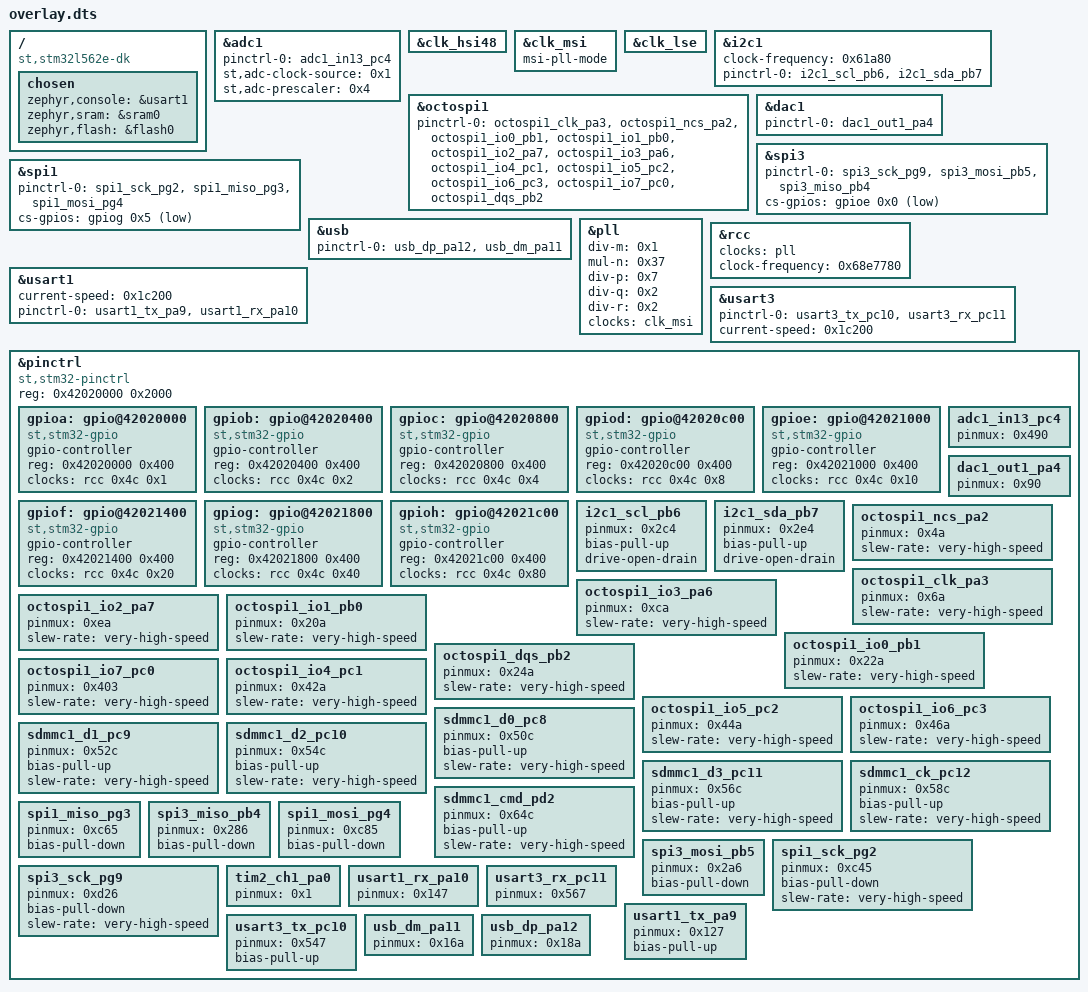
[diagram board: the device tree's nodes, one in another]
/ {
	compatible = "st,stm32l562e-dk";
	chosen {
		zephyr,console = &usart1;
		zephyr,sram = &sram0;
		zephyr,flash = &flash0;
	};
};
&adc1{
	status = "okay";
	pinctrl-0 = < &adc1_in13_pc4 >;
	pinctrl-names = "default";
	st,adc-clock-source = < 0x1 >;
	st,adc-prescaler = < 0x4 >;
};
&clk_hsi48{
	status = "okay";
};
&clk_msi{
	status = "okay";
	msi-pll-mode;
};
&clk_lse{
	status = "okay";
};
&i2c1{
	clock-frequency = < 0x61a80 >;
	status = "okay";
	pinctrl-0 = < &i2c1_scl_pb6 &i2c1_sda_pb7 >;
	pinctrl-names = "default";
};
&octospi1{
	status = "okay";
	pinctrl-0 = < &octospi1_clk_pa3 &octospi1_ncs_pa2 &octospi1_io0_pb1 &octospi1_io1_pb0 &octospi1_io2_pa7 &octospi1_io3_pa6 &octospi1_io4_pc1 &octospi1_io5_pc2 &octospi1_io6_pc3 &octospi1_io7_pc0 &octospi1_dqs_pb2 >;
	pinctrl-names = "default";
};
&dac1{
	status = "okay";
	pinctrl-0 = < &dac1_out1_pa4 >;
	pinctrl-names = "default";
};
&spi3{
	status = "okay";
	pinctrl-0 = < &spi3_sck_pg9 &spi3_mosi_pb5 &spi3_miso_pb4 >;
	pinctrl-names = "default";
	cs-gpios = < &gpioe 0x0 0x11 >;
};
&spi1{
	status = "okay";
	pinctrl-0 = < &spi1_sck_pg2 &spi1_miso_pg3 &spi1_mosi_pg4 >;
	pinctrl-names = "default";
	cs-gpios = < &gpiog 0x5 0x11 >;
};
&usb{
	status = "okay";
	pinctrl-0 = < &usb_dp_pa12 &usb_dm_pa11 >;
	pinctrl-names = "default";
};
&pll{
	status = "okay";
	div-m = < 0x1 >;
	mul-n = < 0x37 >;
	div-p = < 0x7 >;
	div-q = < 0x2 >;
	div-r = < 0x2 >;
	clocks = < &clk_msi >;
};
&rcc{
	clocks = < &pll >;
	clock-frequency = < 0x68e7780 >;
};
&usart1{
	status = "okay";
	current-speed = < 0x1c200 >;
	pinctrl-0 = < &usart1_tx_pa9 &usart1_rx_pa10 >;
	pinctrl-names = "default";
};
&usart3{
	status = "okay";
	pinctrl-0 = < &usart3_tx_pc10 &usart3_rx_pc11 >;
	pinctrl-names = "default";
	current-speed = < 0x1c200 >;
};
&pinctrl{
	compatible = "st,stm32-pinctrl";
	#address-cells = < 0x1 >;
	#size-cells = < 0x1 >;
	reg = < 0x42020000 0x2000 >;
	gpioa: gpio@42020000 {
		compatible = "st,stm32-gpio";
		gpio-controller;
		#gpio-cells = < 0x2 >;
		reg = < 0x42020000 0x400 >;
		clocks = < &rcc 0x4c 0x1 >;
	};
	gpiob: gpio@42020400 {
		compatible = "st,stm32-gpio";
		gpio-controller;
		#gpio-cells = < 0x2 >;
		reg = < 0x42020400 0x400 >;
		clocks = < &rcc 0x4c 0x2 >;
	};
	gpioc: gpio@42020800 {
		compatible = "st,stm32-gpio";
		gpio-controller;
		#gpio-cells = < 0x2 >;
		reg = < 0x42020800 0x400 >;
		clocks = < &rcc 0x4c 0x4 >;
	};
	gpiod: gpio@42020c00 {
		compatible = "st,stm32-gpio";
		gpio-controller;
		#gpio-cells = < 0x2 >;
		reg = < 0x42020c00 0x400 >;
		clocks = < &rcc 0x4c 0x8 >;
	};
	gpioe: gpio@42021000 {
		compatible = "st,stm32-gpio";
		gpio-controller;
		#gpio-cells = < 0x2 >;
		reg = < 0x42021000 0x400 >;
		clocks = < &rcc 0x4c 0x10 >;
	};
	gpiof: gpio@42021400 {
		compatible = "st,stm32-gpio";
		gpio-controller;
		#gpio-cells = < 0x2 >;
		reg = < 0x42021400 0x400 >;
		clocks = < &rcc 0x4c 0x20 >;
	};
	gpiog: gpio@42021800 {
		compatible = "st,stm32-gpio";
		gpio-controller;
		#gpio-cells = < 0x2 >;
		reg = < 0x42021800 0x400 >;
		clocks = < &rcc 0x4c 0x40 >;
	};
	gpioh: gpio@42021c00 {
		compatible = "st,stm32-gpio";
		gpio-controller;
		#gpio-cells = < 0x2 >;
		reg = < 0x42021c00 0x400 >;
		clocks = < &rcc 0x4c 0x80 >;
	};
	adc1_in13_pc4: adc1_in13_pc4 {
		pinmux = < 0x490 >;
	};
	dac1_out1_pa4: dac1_out1_pa4 {
		pinmux = < 0x90 >;
	};
	i2c1_scl_pb6: i2c1_scl_pb6 {
		pinmux = < 0x2c4 >;
		bias-pull-up;
		drive-open-drain;
	};
	i2c1_sda_pb7: i2c1_sda_pb7 {
		pinmux = < 0x2e4 >;
		bias-pull-up;
		drive-open-drain;
	};
	octospi1_ncs_pa2: octospi1_ncs_pa2 {
		pinmux = < 0x4a >;
		slew-rate = "very-high-speed";
	};
	octospi1_clk_pa3: octospi1_clk_pa3 {
		pinmux = < 0x6a >;
		slew-rate = "very-high-speed";
	};
	octospi1_io3_pa6: octospi1_io3_pa6 {
		pinmux = < 0xca >;
		slew-rate = "very-high-speed";
	};
	octospi1_io2_pa7: octospi1_io2_pa7 {
		pinmux = < 0xea >;
		slew-rate = "very-high-speed";
	};
	octospi1_io1_pb0: octospi1_io1_pb0 {
		pinmux = < 0x20a >;
		slew-rate = "very-high-speed";
	};
	octospi1_io0_pb1: octospi1_io0_pb1 {
		pinmux = < 0x22a >;
		slew-rate = "very-high-speed";
	};
	octospi1_dqs_pb2: octospi1_dqs_pb2 {
		pinmux = < 0x24a >;
		slew-rate = "very-high-speed";
	};
	octospi1_io7_pc0: octospi1_io7_pc0 {
		pinmux = < 0x403 >;
		slew-rate = "very-high-speed";
	};
	octospi1_io4_pc1: octospi1_io4_pc1 {
		pinmux = < 0x42a >;
		slew-rate = "very-high-speed";
	};
	octospi1_io5_pc2: octospi1_io5_pc2 {
		pinmux = < 0x44a >;
		slew-rate = "very-high-speed";
	};
	octospi1_io6_pc3: octospi1_io6_pc3 {
		pinmux = < 0x46a >;
		slew-rate = "very-high-speed";
	};
	sdmmc1_d0_pc8: sdmmc1_d0_pc8 {
		pinmux = < 0x50c >;
		bias-pull-up;
		slew-rate = "very-high-speed";
	};
	sdmmc1_d1_pc9: sdmmc1_d1_pc9 {
		pinmux = < 0x52c >;
		bias-pull-up;
		slew-rate = "very-high-speed";
	};
	sdmmc1_d2_pc10: sdmmc1_d2_pc10 {
		pinmux = < 0x54c >;
		bias-pull-up;
		slew-rate = "very-high-speed";
	};
	sdmmc1_d3_pc11: sdmmc1_d3_pc11 {
		pinmux = < 0x56c >;
		bias-pull-up;
		slew-rate = "very-high-speed";
	};
	sdmmc1_ck_pc12: sdmmc1_ck_pc12 {
		pinmux = < 0x58c >;
		bias-pull-up;
		slew-rate = "very-high-speed";
	};
	sdmmc1_cmd_pd2: sdmmc1_cmd_pd2 {
		pinmux = < 0x64c >;
		bias-pull-up;
		slew-rate = "very-high-speed";
	};
	spi1_miso_pg3: spi1_miso_pg3 {
		pinmux = < 0xc65 >;
		bias-pull-down;
	};
	spi3_miso_pb4: spi3_miso_pb4 {
		pinmux = < 0x286 >;
		bias-pull-down;
	};
	spi1_mosi_pg4: spi1_mosi_pg4 {
		pinmux = < 0xc85 >;
		bias-pull-down;
	};
	spi3_mosi_pb5: spi3_mosi_pb5 {
		pinmux = < 0x2a6 >;
		bias-pull-down;
	};
	spi1_sck_pg2: spi1_sck_pg2 {
		pinmux = < 0xc45 >;
		bias-pull-down;
		slew-rate = "very-high-speed";
	};
	spi3_sck_pg9: spi3_sck_pg9 {
		pinmux = < 0xd26 >;
		bias-pull-down;
		slew-rate = "very-high-speed";
	};
	tim2_ch1_pa0: tim2_ch1_pa0 {
		pinmux = < 0x1 >;
	};
	usart1_rx_pa10: usart1_rx_pa10 {
		pinmux = < 0x147 >;
	};
	usart3_rx_pc11: usart3_rx_pc11 {
		pinmux = < 0x567 >;
	};
	usart1_tx_pa9: usart1_tx_pa9 {
		pinmux = < 0x127 >;
		bias-pull-up;
	};
	usart3_tx_pc10: usart3_tx_pc10 {
		pinmux = < 0x547 >;
		bias-pull-up;
	};
	usb_dm_pa11: usb_dm_pa11 {
		pinmux = < 0x16a >;
	};
	usb_dp_pa12: usb_dp_pa12 {
		pinmux = < 0x18a >;
	};
};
